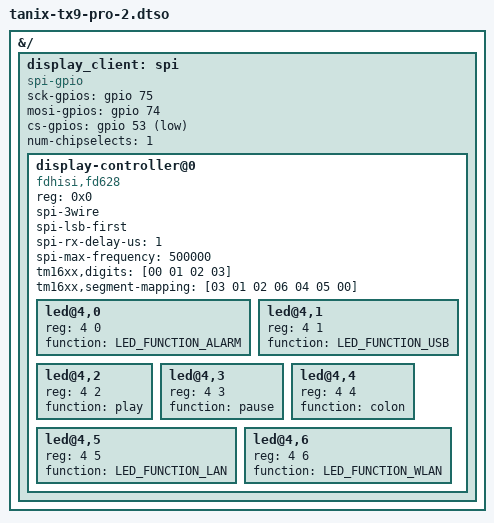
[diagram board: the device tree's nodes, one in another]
/dts-v1/;
/plugin/;

#include <dt-bindings/gpio/gpio.h>
#include <dt-bindings/leds/common.h>

&{/} {

	display_client: spi {
		#address-cells = <1>;
		#size-cells = <0>;
		compatible = "spi-gpio";
		sck-gpios = <&gpio 75 GPIO_ACTIVE_HIGH>;
		mosi-gpios = <&gpio 74 GPIO_ACTIVE_HIGH>;
		cs-gpios = <&gpio 53 GPIO_ACTIVE_LOW>;
		num-chipselects = <1>;

		display-controller@0 {
			compatible = "fdhisi,fd628";
			reg = <0x0>;
			spi-3wire;
			spi-lsb-first;
			spi-rx-delay-us = <1>;
			spi-max-frequency = <500000>;

			tm16xx,digits = [00 01 02 03];
			tm16xx,segment-mapping = [03 01 02 06 04 05 00];

			#address-cells = <2>;
			#size-cells = <0>;
			
			led@4,0 {
				reg = <4 0>;
				function = LED_FUNCTION_ALARM;
			};
			
			led@4,1 {
				reg = <4 1>;
				function = LED_FUNCTION_USB;
			};
			
			led@4,2 {
				reg = <4 2>;
				function = "play";
			};
			
			led@4,3 {
				reg = <4 3>;
				function = "pause";
			};
			
			led@4,4 {
				reg = <4 4>;
				function = "colon";
			};
			
			led@4,5 {
				reg = <4 5>;
				function = LED_FUNCTION_LAN;
			};
			
			led@4,6 {
				reg = <4 6>;
				function = LED_FUNCTION_WLAN;
			};

		};
	};
};

